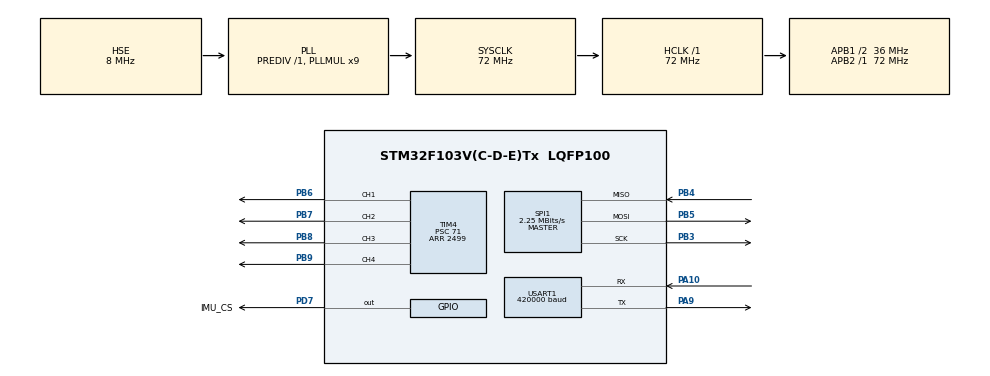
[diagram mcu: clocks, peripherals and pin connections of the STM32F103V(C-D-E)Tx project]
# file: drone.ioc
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Dma.Request0=USART1_RX
Dma.USART1_RX.0.Direction=DMA_PERIPH_TO_MEMORY
Dma.USART1_RX.0.Instance=DMA1_Channel5
Dma.USART1_RX.0.MemDataAlignment=DMA_MDATAALIGN_BYTE
Dma.USART1_RX.0.MemInc=DMA_MINC_ENABLE
Dma.USART1_RX.0.Mode=DMA_CIRCULAR
Dma.USART1_RX.0.PeriphDataAlignment=DMA_PDATAALIGN_BYTE
Dma.USART1_RX.0.PeriphInc=DMA_PINC_DISABLE
Dma.USART1_RX.0.Priority=DMA_PRIORITY_HIGH
Mcu.Family=STM32F1
Mcu.Name=STM32F103V(C-D-E)Tx
Mcu.Package=LQFP100
NVIC.DMA1_Channel5_IRQn=true\:5\:0\:false\:false\:true\:false\:true\:true
NVIC.PriorityGroup=NVIC_PRIORITYGROUP_4
NVIC.USART1_IRQn=true\:5\:0\:false\:false\:true\:false\:true\:true
OSC_IN.Mode=HSE-External-Oscillator
OSC_IN.Signal=RCC_OSC_IN
OSC_OUT.Mode=HSE-External-Oscillator
OSC_OUT.Signal=RCC_OSC_OUT
PA10.Mode=Asynchronous
PA10.Signal=USART1_RX
PA13.Mode=Serial_Wire
PA13.Signal=SYS_JTMS-SWDIO
PA14.Mode=Serial_Wire
PA14.Signal=SYS_JTCK-SWCLK
PA9.Mode=Asynchronous
PA9.Signal=USART1_TX
PB3.Mode=Full_Duplex_Master
PB3.Signal=SPI1_SCK
PB4.Mode=Full_Duplex_Master
PB4.Signal=SPI1_MISO
PB5.Mode=Full_Duplex_Master
PB5.Signal=SPI1_MOSI
PB6.Signal=S_TIM4_CH1
PB7.Signal=S_TIM4_CH2
PB8.Signal=S_TIM4_CH3
PB9.Signal=S_TIM4_CH4
PD7.GPIO_Label=IMU_CS
PD7.PinState=GPIO_PIN_SET
PD7.Signal=GPIO_Output
ProjectManager.HeapSize=0x200
ProjectManager.StackSize=0x400
ProjectManager.TargetToolchain=CMake
RCC.AHBFreq_Value=72000000
RCC.APB1CLKDivider=RCC_HCLK_DIV2
RCC.APB1Freq_Value=36000000
RCC.APB1TimFreq_Value=72000000
RCC.APB2Freq_Value=72000000
RCC.APB2TimFreq_Value=72000000
RCC.HCLKFreq_Value=72000000
RCC.PLLMUL=RCC_PLL_MUL9
RCC.PLLSourceVirtual=RCC_PLLSOURCE_HSE
RCC.SYSCLKFreq_VALUE=72000000
RCC.SYSCLKSource=RCC_SYSCLKSOURCE_PLLCLK
RCC.USBFreq_Value=72000000
SH.S_TIM4_CH1.0=TIM4_CH1,PWM Generation1 CH1
SH.S_TIM4_CH2.0=TIM4_CH2,PWM Generation2 CH2
SH.S_TIM4_CH3.0=TIM4_CH3,PWM Generation3 CH3
SH.S_TIM4_CH4.0=TIM4_CH4,PWM Generation4 CH4
SPI1.BaudRatePrescaler=SPI_BAUDRATEPRESCALER_32
SPI1.CalculateBaudRate=2.25 MBits/s
SPI1.Direction=SPI_DIRECTION_2LINES
SPI1.Mode=SPI_MODE_MASTER
SPI1.VirtualType=VM_MASTER
TIM4.Channel-PWM\ Generation1\ CH1=TIM_CHANNEL_1
TIM4.Channel-PWM\ Generation2\ CH2=TIM_CHANNEL_2
TIM4.Channel-PWM\ Generation3\ CH3=TIM_CHANNEL_3
TIM4.Channel-PWM\ Generation4\ CH4=TIM_CHANNEL_4
TIM4.Period=2499
TIM4.Prescaler=71
TIM4.Pulse-PWM\ Generation1\ CH1=1000
TIM4.Pulse-PWM\ Generation2\ CH2=1000
TIM4.Pulse-PWM\ Generation3\ CH3=1000
TIM4.Pulse-PWM\ Generation4\ CH4=1000
USART1.BaudRate=420000
USART1.VirtualMode=VM_ASYNC
VP_TIM4_VS_ClockSourceINT.Mode=Internal
board=custom

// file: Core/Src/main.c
/* USER CODE BEGIN Header */
/**
  ******************************************************************************
  * @file           : main.c
  * @brief          : Main program body
  ******************************************************************************
  * @attention
  *
  * Copyright (c) 2026 STMicroelectronics.
  * All rights reserved.
  *
  * This software is licensed under terms that can be found in the LICENSE file
  * in the root directory of this software component.
  * If no LICENSE file comes with this software, it is provided AS-IS.
  *
  ******************************************************************************
  */
/* USER CODE END Header */
#include "main.h"

/* USER CODE BEGIN Includes */
#include "app.h"

/* USER CODE END Includes */

SPI_HandleTypeDef hspi1;

TIM_HandleTypeDef htim4;

UART_HandleTypeDef huart1;
DMA_HandleTypeDef hdma_usart1_rx;

void SystemClock_Config(void);
static void MX_GPIO_Init(void);
static void MX_DMA_Init(void);
static void MX_SPI1_Init(void);
static void MX_USART1_UART_Init(void);
static void MX_TIM4_Init(void);

int main(void)
{

  /* MCU Configuration--------------------------------------------------------*/

  /* Reset of all peripherals, Initializes the Flash interface and the Systick. */
  HAL_Init();

  /* Configure the system clock */
  SystemClock_Config();

  /* Initialize all configured peripherals */
  MX_GPIO_Init();
  MX_DMA_Init();
  MX_SPI1_Init();
  MX_USART1_UART_Init();
  MX_TIM4_Init();
  /* USER CODE BEGIN 2 */
  app_init();

  /* USER CODE END 2 */

  /* Infinite loop */
  while (1)
  {

    /* USER CODE BEGIN 3 */
    app_process();
  }
  /* USER CODE END 3 */
}

void SystemClock_Config(void)
{
  RCC_OscInitTypeDef RCC_OscInitStruct = {0};
  RCC_ClkInitTypeDef RCC_ClkInitStruct = {0};

  /** Initializes the RCC Oscillators according to the specified parameters
  * in the RCC_OscInitTypeDef structure.
  */
  RCC_OscInitStruct.OscillatorType = RCC_OSCILLATORTYPE_HSE;
  RCC_OscInitStruct.HSEState = RCC_HSE_ON;
  RCC_OscInitStruct.HSEPredivValue = RCC_HSE_PREDIV_DIV1;
  RCC_OscInitStruct.HSIState = RCC_HSI_ON;
  RCC_OscInitStruct.PLL.PLLState = RCC_PLL_ON;
  RCC_OscInitStruct.PLL.PLLSource = RCC_PLLSOURCE_HSE;
  RCC_OscInitStruct.PLL.PLLMUL = RCC_PLL_MUL9;
  if (HAL_RCC_OscConfig(&RCC_OscInitStruct) != HAL_OK)
  {
    Error_Handler();
  }

  /** Initializes the CPU, AHB and APB buses clocks
  */
  RCC_ClkInitStruct.ClockType = RCC_CLOCKTYPE_HCLK|RCC_CLOCKTYPE_SYSCLK
                              |RCC_CLOCKTYPE_PCLK1|RCC_CLOCKTYPE_PCLK2;
  RCC_ClkInitStruct.SYSCLKSource = RCC_SYSCLKSOURCE_PLLCLK;
  RCC_ClkInitStruct.AHBCLKDivider = RCC_SYSCLK_DIV1;
  RCC_ClkInitStruct.APB1CLKDivider = RCC_HCLK_DIV2;
  RCC_ClkInitStruct.APB2CLKDivider = RCC_HCLK_DIV1;

  if (HAL_RCC_ClockConfig(&RCC_ClkInitStruct, FLASH_LATENCY_2) != HAL_OK)
  {
    Error_Handler();
  }
}

static void MX_SPI1_Init(void)
{

  /* SPI1 parameter configuration*/
  hspi1.Instance = SPI1;
  hspi1.Init.Mode = SPI_MODE_MASTER;
  hspi1.Init.Direction = SPI_DIRECTION_2LINES;
  hspi1.Init.DataSize = SPI_DATASIZE_8BIT;
  hspi1.Init.CLKPolarity = SPI_POLARITY_LOW;
  hspi1.Init.CLKPhase = SPI_PHASE_1EDGE;
  hspi1.Init.NSS = SPI_NSS_SOFT;
  hspi1.Init.BaudRatePrescaler = SPI_BAUDRATEPRESCALER_32;
  hspi1.Init.FirstBit = SPI_FIRSTBIT_MSB;
  hspi1.Init.TIMode = SPI_TIMODE_DISABLE;
  hspi1.Init.CRCCalculation = SPI_CRCCALCULATION_DISABLE;
  hspi1.Init.CRCPolynomial = 10;
  if (HAL_SPI_Init(&hspi1) != HAL_OK)
  {
    Error_Handler();
  }

}

static void MX_TIM4_Init(void)
{

  TIM_ClockConfigTypeDef sClockSourceConfig = {0};
  TIM_MasterConfigTypeDef sMasterConfig = {0};
  TIM_OC_InitTypeDef sConfigOC = {0};

  htim4.Instance = TIM4;
  htim4.Init.Prescaler = 71;
  htim4.Init.CounterMode = TIM_COUNTERMODE_UP;
  htim4.Init.Period = 2499;
  htim4.Init.ClockDivision = TIM_CLOCKDIVISION_DIV1;
  htim4.Init.AutoReloadPreload = TIM_AUTORELOAD_PRELOAD_DISABLE;
  if (HAL_TIM_Base_Init(&htim4) != HAL_OK)
  {
    Error_Handler();
  }
  sClockSourceConfig.ClockSource = TIM_CLOCKSOURCE_INTERNAL;
  if (HAL_TIM_ConfigClockSource(&htim4, &sClockSourceConfig) != HAL_OK)
  {
    Error_Handler();
  }
  if (HAL_TIM_PWM_Init(&htim4) != HAL_OK)
  {
    Error_Handler();
  }
  sMasterConfig.MasterOutputTrigger = TIM_TRGO_RESET;
  sMasterConfig.MasterSlaveMode = TIM_MASTERSLAVEMODE_DISABLE;
  if (HAL_TIMEx_MasterConfigSynchronization(&htim4, &sMasterConfig) != HAL_OK)
  {
    Error_Handler();
  }
  sConfigOC.OCMode = TIM_OCMODE_PWM1;
  sConfigOC.Pulse = 1000;
  sConfigOC.OCPolarity = TIM_OCPOLARITY_HIGH;
  sConfigOC.OCFastMode = TIM_OCFAST_DISABLE;
  if (HAL_TIM_PWM_ConfigChannel(&htim4, &sConfigOC, TIM_CHANNEL_1) != HAL_OK)
  {
    Error_Handler();
  }
  if (HAL_TIM_PWM_ConfigChannel(&htim4, &sConfigOC, TIM_CHANNEL_2) != HAL_OK)
  {
    Error_Handler();
  }
  if (HAL_TIM_PWM_ConfigChannel(&htim4, &sConfigOC, TIM_CHANNEL_3) != HAL_OK)
  {
    Error_Handler();
  }
  if (HAL_TIM_PWM_ConfigChannel(&htim4, &sConfigOC, TIM_CHANNEL_4) != HAL_OK)
  {
    Error_Handler();
  }
  HAL_TIM_MspPostInit(&htim4);

}

static void MX_USART1_UART_Init(void)
{

  huart1.Instance = USART1;
  huart1.Init.BaudRate = 420000;
  huart1.Init.WordLength = UART_WORDLENGTH_8B;
  huart1.Init.StopBits = UART_STOPBITS_1;
  huart1.Init.Parity = UART_PARITY_NONE;
  huart1.Init.Mode = UART_MODE_TX_RX;
  huart1.Init.HwFlowCtl = UART_HWCONTROL_NONE;
  huart1.Init.OverSampling = UART_OVERSAMPLING_16;
  if (HAL_UART_Init(&huart1) != HAL_OK)
  {
    Error_Handler();
  }

}

static void MX_DMA_Init(void)
{

  /* DMA controller clock enable */
  __HAL_RCC_DMA1_CLK_ENABLE();

  /* DMA interrupt init */
  /* DMA1_Channel5_IRQn interrupt configuration */
  HAL_NVIC_SetPriority(DMA1_Channel5_IRQn, 5, 0);
  HAL_NVIC_EnableIRQ(DMA1_Channel5_IRQn);

}

static void MX_GPIO_Init(void)
{
  GPIO_InitTypeDef GPIO_InitStruct = {0};

  /* GPIO Ports Clock Enable */
  __HAL_RCC_GPIOA_CLK_ENABLE();
  __HAL_RCC_GPIOD_CLK_ENABLE();
  __HAL_RCC_GPIOB_CLK_ENABLE();

  /*Configure GPIO pin Output Level */
  HAL_GPIO_WritePin(IMU_CS_GPIO_Port, IMU_CS_Pin, GPIO_PIN_SET);

  /*Configure GPIO pin : IMU_CS_Pin */
  GPIO_InitStruct.Pin = IMU_CS_Pin;
  GPIO_InitStruct.Mode = GPIO_MODE_OUTPUT_PP;
  GPIO_InitStruct.Pull = GPIO_NOPULL;
  GPIO_InitStruct.Speed = GPIO_SPEED_FREQ_LOW;
  HAL_GPIO_Init(IMU_CS_GPIO_Port, &GPIO_InitStruct);

}

void Error_Handler(void)
{
  __disable_irq();
  while (1)
  {
  }
}
